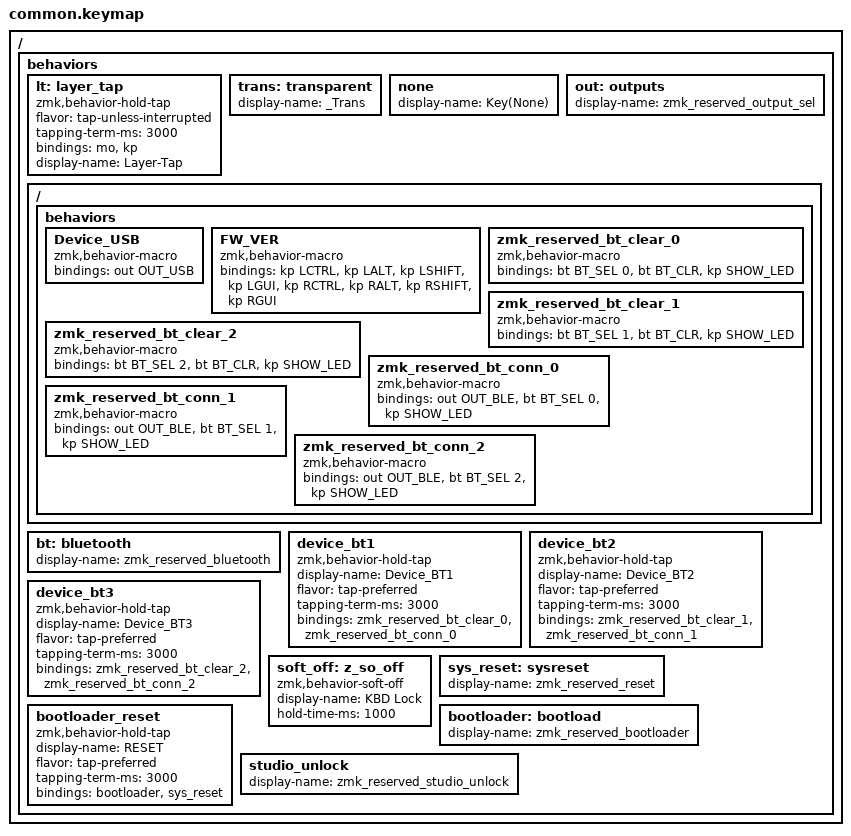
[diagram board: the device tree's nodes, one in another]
/*
 * Copyright (c) 2021 The ZMK Contributors
 *
 * SPDX-License-Identifier: MIT
 */
#define FW_VER zmk_firmware_version_260830

#include <behaviors.dtsi>
#include <dt-bindings/zmk/keys.h>
#include <dt-bindings/zmk/pointing.h>
#include <dt-bindings/zmk/bt.h>
#include <dt-bindings/zmk/outputs.h>

/ {
    behaviors {
        lt: layer_tap {
            compatible = "zmk,behavior-hold-tap";
            #binding-cells = <2>;
            flavor = "tap-unless-interrupted";
            tapping-term-ms = <3000>;
            bindings = <&mo>, <&kp>;
            display-name = "Layer-Tap";
        };

        
        trans: transparent { display-name = "_Trans"; };
        none: none { display-name = "Key(None)"; };
        

        #if 1
        out: outputs { display-name = "zmk_reserved_output_sel"; };
        ZMK_MACRO(Device_USB, bindings = <&out OUT_USB>;)

        bt: bluetooth { display-name = "zmk_reserved_bluetooth"; };
        
        #define SHOW_LED 0xAB //A5-AF Reserved
        ZMK_MACRO(FW_VER, bindings = <&kp LCTRL &kp LALT &kp LSHIFT &kp LGUI &kp RCTRL &kp RALT &kp RSHIFT &kp RGUI>;)
        ZMK_MACRO(zmk_reserved_bt_clear_0, bindings = <&bt BT_SEL 0>, <&bt BT_CLR>, <&kp SHOW_LED>;)
        ZMK_MACRO(zmk_reserved_bt_clear_1, bindings = <&bt BT_SEL 1>, <&bt BT_CLR>, <&kp SHOW_LED>;)
        ZMK_MACRO(zmk_reserved_bt_clear_2, bindings = <&bt BT_SEL 2>, <&bt BT_CLR>, <&kp SHOW_LED>;)
        ZMK_MACRO(zmk_reserved_bt_conn_0,  bindings = <&out OUT_BLE>, <&bt BT_SEL 0>, <&kp SHOW_LED>;)
        ZMK_MACRO(zmk_reserved_bt_conn_1,  bindings = <&out OUT_BLE>, <&bt BT_SEL 1>, <&kp SHOW_LED>;)
        ZMK_MACRO(zmk_reserved_bt_conn_2,  bindings = <&out OUT_BLE>, <&bt BT_SEL 2>, <&kp SHOW_LED>;)

        device_bt1: device_bt1 {
            compatible = "zmk,behavior-hold-tap";
            display-name = "Device_BT1";
            #binding-cells = <2>;
            flavor = "tap-preferred";
            tapping-term-ms = <3000>;  // delay amount in ms
            bindings = <&zmk_reserved_bt_clear_0>, <&zmk_reserved_bt_conn_0>;
        };
        device_bt2: device_bt2 {
            compatible = "zmk,behavior-hold-tap";
            display-name = "Device_BT2";
            #binding-cells = <2>;
            flavor = "tap-preferred";
            tapping-term-ms = <3000>;  // delay amount in ms
            bindings = <&zmk_reserved_bt_clear_1>, <&zmk_reserved_bt_conn_1>;
        };
        device_bt3: device_bt3 {
            compatible = "zmk,behavior-hold-tap";
            display-name = "Device_BT3";
            #binding-cells = <2>;
            flavor = "tap-preferred";
            tapping-term-ms = <3000>;  // delay amount in ms
            bindings = <&zmk_reserved_bt_clear_2>, <&zmk_reserved_bt_conn_2>;
        };
        //
        soft_off: z_so_off {
            compatible = "zmk,behavior-soft-off";
            display-name = "KBD Lock";
            #binding-cells = <0>;
            hold-time-ms = <1000>;
        };

        sys_reset: sysreset { display-name = "zmk_reserved_reset"; };
        bootloader: bootload { display-name = "zmk_reserved_bootloader"; };
        
        bootloader_reset:bootloader_reset {
            compatible = "zmk,behavior-hold-tap";
            display-name = "RESET";
            #binding-cells = <2>;
            flavor = "tap-preferred";
            tapping-term-ms = <3000>;  // delay amount in ms
            bindings = <&bootloader>, <&sys_reset>;
        };
        
        studio_unlock: studio_unlock { display-name = "zmk_reserved_studio_unlock"; };
        #endif
        
    };   
};
